# AE402FA0E5597LE0_CM55_HP_View register map
Vendor: Alif Semiconductor; Series: E4; File version: 1.0
CPU: CM55 r1p0, selectable endian, MPU, FPU, double-precision FPU, DSP, VTOR, 8 interrupt priority bits, 1 SAU regions
Registers are 32-bit, read-write, reset 0x0 unless marked. A register's access mark holds for its fields unless they carry their own. Offsets are from the block's base; [hi:lo] are bit positions; 'fields as' and 'values as' point back to an identical list.

## ETH (part 3 of 4)
Base 0x48100000
0xB18 ETH_MAC_TIMESTAMP_ADDEND — Timestamp Addend Register
  [31:0] TSAR — Timestamp Addend Register This field indicates the 32-bit time value to be added to the Accumulator register to achieve time synchronization.
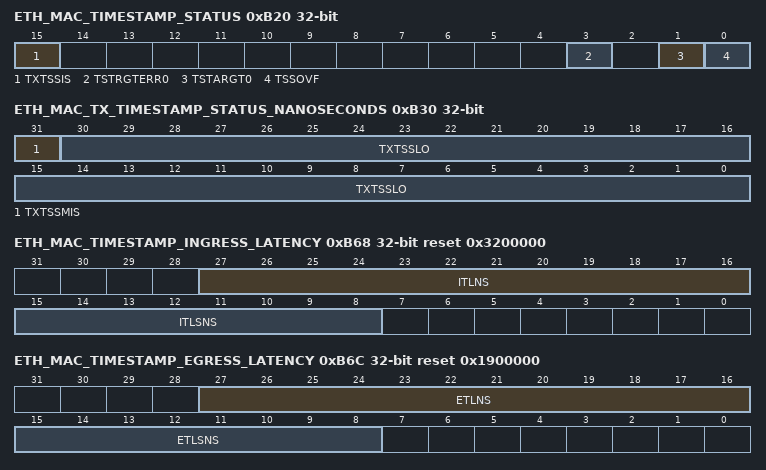
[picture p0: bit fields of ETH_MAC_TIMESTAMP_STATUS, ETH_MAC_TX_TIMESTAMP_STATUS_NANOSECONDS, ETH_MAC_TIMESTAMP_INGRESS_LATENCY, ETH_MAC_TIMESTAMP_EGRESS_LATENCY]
0xB20 ETH_MAC_TIMESTAMP_STATUS ro — Timestamp Status Register
  [15] TXTSSIS — Tx Timestamp Status Interrupt Status When drop transmit status is enabled in MTL, this bit is set when the captured transmit timestamp is updated in the ETH_MAC_TX_TIMESTAMP_STATUS_NANOSECONDS and ETH_MAC_TX_TIMESTAMP_STATUS_SECONDS registers. This bit is cleared when the ETH_MAC_TX_TIMESTAMP_STATUS_SECONDS register is read (or write to ETH_MAC_TX_TIMESTAMP_STATUS_SECONDS register when the ETH_MAC_CSR_SW_CTRL[RCWE] bit is set).
    0=Tx timestamp status interrupt status not detected; 1=Tx timestamp status interrupt status detected
  [3] TSTRGTERR0 — Timestamp Target Time Error This bit is set when the latest target time programmed in the ETH_MAC_PPS0_TARGET_TIME_SECONDS and ETH_MAC_PPS0_TARGET_TIME_NANOSECONDS registers elapses. Access restriction applies. Clears on read (or this bit is written to 1 when the ETH_MAC_CSR_SW_CTRL[RCWE] bit is set). Self-set to 1 on internal event.
    0=Timestamp target time error status not detected; 1=Timestamp target time error status detected
  [1] TSTARGT0 — Timestamp Target Time Reached When this bit is set, it indicates that the value of system time is greater than or equal to the value specified in the ETH_MAC_PPS0_TARGET_TIME_SECONDS and ETH_MAC_PPS0_TARGET_TIME_NANOSECONDS registers. Access restriction applies. Clears on read (or this bit is written to 1 when the ETH_MAC_CSR_SW_CTRL[RCWE] bit is set). Self-set to 1 on internal event.
    0=Timestamp target time reached status not detected; 1=Timestamp target time reached status detected
  [0] TSSOVF — Timestamp Seconds Overflow When this bit is set, it indicates that the ETH_MAC_SYSTEM_TIME_SECONDS[TSS] value has overflowed beyond 0xFFFF_FFFF. Access restriction applies. Clears on read (or this bit is written to 1 when the ETH_MAC_CSR_SW_CTRL[RCWE] bit is set). Self-set to 1 on internal event.
    0=Timestamp seconds overflow status not detected; 1=Timestamp seconds overflow status detected
0xB24 ETH_MAC_RX_DOMAIN_TIME_INCR — Rx Domain Time Increment Register
  [31:16] RXNS — Receive Domain Time Increment Value in Nanoseconds This field indicates the Nanosecond part of the increment value of the PTP time maintained in Receive clock domain that is used for timestamping.
0xB28 ETH_MAC_TX_DOMAIN_TIME_INCR — Tx Domain Time Increment Register
  [31:16] TXNS — Transmit Domain Time Increment Value in Nanoseconds This field indicates the Nanosecond part of the increment value of the PTP time maintained in Transmit clock domain that is used for timestamping.
0xB30 ETH_MAC_TX_TIMESTAMP_STATUS_NANOSECONDS ro — Transmit Timestamp Status Nanoseconds Register
  [31] TXTSSMIS — Transmit Timestamp Status Missed When this bit is set, it indicates one of the following: The timestamp of the current packet is ignored if the ETH_MAC_TIMESTAMP_CONTROL[TXTSSTSM] bit is reset The timestamp of the previous packet is overwritten with timestamp of the current packet if the ETH_MAC_TIMESTAMP_CONTROL[TXTSSTSM] bit is set. Access restriction applies. Clears on read. Self-set to 1 on internal event.
    0=Transmit timestamp status missed status not detected; 1=Transmit timestamp status missed status detected
  [30:0] TXTSSLO — Transmit Timestamp Status Low This field contains the 31 bits of the Nanoseconds field of the Transmit packet's captured timestamp.
0xB34 ETH_MAC_TX_TIMESTAMP_STATUS_SECONDS ro — Transmit Timestamp Status Seconds Register
  [31:0] TXTSSHI — Transmit Timestamp Status High This field contains the lower 32 bits of the Seconds field of Transmit packet's captured timestamp.
0xB58 ETH_MAC_TIMESTAMP_INGRESS_CORR_NANOSECOND — Timestamp Ingress Correction Nanoseconds Register
  [31:0] TSIC — Timestamp Ingress Correction This field contains the ingress path correction value as defined by the Ingress Correction expression.
0xB5C ETH_MAC_TIMESTAMP_EGRESS_CORR_NANOSECOND — Timestamp Egress Correction Nanoseconds Register
  [31:0] TSEC — Timestamp Egress Correction This field contains the nanoseconds part of the egress path correction value as defined by the Egress Correction expression.
0xB68 ETH_MAC_TIMESTAMP_INGRESS_LATENCY ro reset 0x3200000 — Ingress MAC latency Register
  [27:16] ITLNS — Ingress Timestamp Latency, in nanoseconds This register holds the average latency in nanoseconds between the input ports (ETH_RXD[1-0]) of MAC and the actual point (RMII) where the ingress timestamp is taken.
  [15:8] ITLSNS — Ingress Timestamp Latency, in sub-nanoseconds This register holds the average latency in sub-nanoseconds between the input ports (ETH_RXD[1-0]) of MAC and the actual point (RMII) where the ingress timestamp is taken.
0xB6C ETH_MAC_TIMESTAMP_EGRESS_LATENCY ro reset 0x1900000 — Egress MAC latency Register
  [27:16] ETLNS — Egress Timestamp Latency, in nanoseconds This register holds the average latency in nanoseconds between the actual point (RMII) where the egress timestamp is taken and the output ports (ETH_TXD[1-0]) of the MAC.
  [15:8] ETLSNS — Egress Timestamp Latency, in sub-nanoseconds This register holds the average latency in sub-nanoseconds between the actual point (RMII) where the egress timestamp is taken and the output ports (ETH_TXD[1-0]) of the MAC.
0xB70 ETH_MAC_PPS_CONTROL — PPS Control Register
  [3:0] PPSCTRL — Pulse Per Second (PPS) Frequency Control This field controls the PPS frequency. The default value of PPSCTRL is 0x0, and the PPS frequency is 1 pulse every second. For other values of PPSCTRL, the PPS becomes a generated clock of the following frequencies: Note: In the binary rollover mode, the PPS frequency has a duty cycle of 50 percent with these frequencies. In the digital rollover mode, the PPS frequency is an average number. The actual clock is of different frequency that gets synchronized every second. For example: When PPSCTRL = 0x1, the PPS (1 Hz) has a low period of 537 ms and a high period of 463 ms When PPSCTRL = 0x2, the PPS (2 Hz) is a sequence of: - One clock of 50 percent duty cycle and 537 ms period - Second clock of 463 ms period (268 ms low and 195 ms high) When PPSCTRL = 0x3, the PPS (4 Hz) is a sequence of: - Fourth clock of 195 ms period (134 ms low and 61 ms high) This behavior is because of the non-linear toggling of bits in the digital rollover mode in the ETH_MAC_SYSTEM_TIME_NANOSECONDS register.
    1=The binary rollover is 2 Hz, and the digital rollover is 1 Hz; 2=The binary rollover is 4 Hz, and the digital rollover is 2 Hz; 3=The binary rollover is 8 Hz, and the digital rollover is 4 Hz; 4=The binary rollover is 16 Hz, and the digital rollover is 8 Hz; 15=The binary rollover is 32.768 kHz and the digital rollover is 16.384 kHz
0xB80 ETH_MAC_PPS0_TARGET_TIME_SECONDS — PPS0 Target Time Seconds Register
  [31:0] TSTRH0 — PPS Target Time Seconds This field stores the time in seconds. When the timestamp value matches or exceeds both ETH_MAC_PPS0_TARGET_TIME_SECONDS and ETH_MAC_PPS0_TARGET_TIME_NANOSECONDS registers, the MAC generates an interrupt (if enabled).
0xB84 ETH_MAC_PPS0_TARGET_TIME_NANOSECONDS — PPS0 Target Time Nanoseconds Register
  [30:0] TTSL0 — Target Time Low for PPS Register This register stores the time in (signed) nanoseconds. When the value of the timestamp matches the value in both ETH_MAC_PPS0_TARGET_TIME_SECONDS and ETH_MAC_PPS0_TARGET_TIME_NANOSECONDS registers, the MAC generates an interrupt (if enabled). When the ETH_MAC_TIMESTAMP_CONTROL[TSCTRLSSR] bit is reset, this value must be (time in ns / 0.465). When the ETH_MAC_TIMESTAMP_CONTROL[TSCTRLSSR] bit is set, this value must not exceed 0x3B9A_C9FF. Access restriction applies. Setting 1 sets. Self-cleared. Setting 0 has no effect.
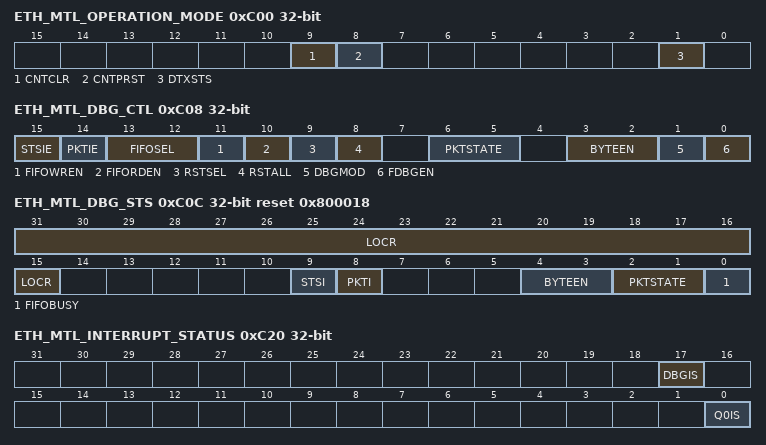
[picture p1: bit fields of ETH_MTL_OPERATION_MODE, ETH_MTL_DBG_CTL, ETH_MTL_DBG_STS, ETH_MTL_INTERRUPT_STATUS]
0xC00 ETH_MTL_OPERATION_MODE — Operation Mode Register
  [9] CNTCLR — Counters Reset When this bit is set, all counters are reset. This bit is cleared automatically after 1 clock cycle. If this bit is set along with the CNTPRST bit, CNTPRST has precedence. Access restrictions apply. MAC initiates the counters reset when application writes 1. MAC writes 0 after the counters reset is complete. MAC ignores when application writes 0.
    0=Counters are not reset; 1=All counters are reset
  [8] CNTPRST — Counters Preset When this bit is set, The ETH_MTL_TXQ0_UNDERFLOW register is initialized/preset to 0x7F0. The ETH_MTL_RXQ0_MISSED_PACKET_OVERFLOW_CNT[MISPKTCNT] and ETH_MTL_RXQ0_MISSED_PACKET_OVERFLOW_CNT[OVFPKTCNT] fields are initialized/preset to 0x7F0. MAC initiates the counters reset when application writes 1. MAC writes 0 after the counters reset is complete. MAC ignores when application writes 0.
    0=Counters preset is disabled; 1=Counters preset is enabled
  [1] DTXSTS — Drop Transmit Status When this bit is set, the Tx packet status received from the MAC is dropped in the MTL. When this bit is reset, the Tx packet status received from the MAC is forwarded to the application.
    0=Drop transmit status is disabled; 1=Drop transmit status is enabled
0xC08 ETH_MTL_DBG_CTL — FIFO Debug Access Control and Status Register
  [15] STSIE — Transmit Status Available Interrupt Status Enable When this bit is set, an interrupt is generated when Transmit status is available in slave mode.
    0=Transmit packet available interrupt status is disabled; 1=Transmit packet available interrupt status is enabled
  [14] PKTIE — Receive Packet Available Interrupt Status Enable When this bit is set, an interrupt is generated when EOP of received packet is written to the Rx FIFO.
    0=Receive packet available interrupt status is disabled; 1=Receive packet available interrupt status is enabled
  [13:12] FIFOSEL — FIFO Selected for Access This field indicates the FIFO selected for debug access:
    0=Tx FIFO; 1=Tx Status FIFO (only read access when SLVMOD is set) / DC Memory FIFO read-write access when DBGMOD is set; 2=TSO FIFO (cannot be accessed when SLVMOD is set); 3=Rx FIFO
  [11] FIFOWREN — FIFO Write Enable When this bit is set, it enables the Write operation on selected FIFO when FIFO Debug Access is enabled. This bit must not be written to 1 when FIFO Debug Access is not enabled, that is FDBGEN bit is 0. Access restriction applies. Self-cleared. Setting 0 clears. Setting 1 sets.
    0=FIFO write is disabled; 1=FIFO write is enabled
  [10] FIFORDEN — FIFO Read Enable When this bit is set, it enables the Read operation on selected FIFO when FIFO Debug Access is enabled. This bit must not be written to 1 when FIFO Debug Access is not enabled, that is FDBGEN bit is 0. Access restriction applies. Self-cleared. Setting 0 clears. Setting 1 sets.
    0=FIFO read is disabled; 1=FIFO read is enabled
  [9] RSTSEL — Reset Pointers of Selected FIFO When this bit is set, the pointers of the currently-selected FIFO are reset when FIFO Debug Access is enabled. This bit must not be written to 1 when FIFO Debug Access is not enabled, that is FDBGEN bit is 0. Access restriction applies. Self-cleared. Setting 0 clears. Setting 1 sets.
    0=Reset pointers of selected FIFO is disabled; 1=Reset pointers of selected FIFO is enabled
  [8] RSTALL — Reset All Pointers When this bit is set, the pointers of all FIFOs are reset when FIFO Debug Access is enabled. This bit must not be written to 1 when FIFO Debug Access is not enabled, that is FDBGEN bit is 0. Access restriction applies. Self-cleared. Setting 0 clears. Setting 1 sets.
    0=Reset all pointers is disabled; 1=Reset all pointers is enabled
  [6:5] PKTSTATE — Encoded Packet State This field is used to write the control information to the Tx FIFO or Rx FIFO. Tx FIFO: 0x0: Packet data 0x1: Control word 0x2: SOP data 0x3: EOP data Rx FIFO: 0x0: Packet data 0x1: Normal status 0x2: Last status 0x3: EOP
  [3:2] BYTEEN — Byte Enables This field indicates the number of data bytes valid in the data register during Write operation. This is valid only when PKTSTATE is 0x2 (EOP) and Tx FIFO or Rx FIFO is selected.
    0=Byte 0 valid; 1=Byte 0 and Byte 1 are valid; 2=Byte 0, Byte 1, and Byte 2 are valid; 3=All four bytes are valid
  [1] DBGMOD — Debug Mode Access to FIFO When this bit is set, it indicates that the current access to the FIFO is read, write, and debug access (that is, data can be written and read to specified or all locations through FIFO Debug Interface). In this mode, the following access types are allowed: - Read and Write access to Tx FIFO, TSO FIFO, DCACHE FIFO and Rx FIFO - Read access is allowed to Tx Status FIFO. When this bit is reset, it indicates that the current access to the FIFO is slave access bypassing the DMA (that is, packets can be transmitted or received through FIFO Debug Interface). In this mode, the following access are allowed: - Write access to the Tx FIFO - Read access to the Rx FIFO and Tx Status FIFO
    0=Debug mode access to FIFO is disabled; 1=Debug mode access to FIFO is enabled
  [0] FDBGEN — FIFO Debug Access Enable When this bit is set, it indicates that the debug mode access to the FIFO through CSR Slave Interface is enabled. When this bit is reset, it indicates that the FIFO can be accessed only through a master interface.
    0=FIFO debug access through CSR Slave Interface is disabled; 1=FIFO debug access through CSR Slave Interface is enabled
0xC0C ETH_MTL_DBG_STS reset 0x800018 — FIFO Debug Status Register
  [31:15] LOCR ro — Remaining Locations in the FIFO Slave Access Mode: This field indicates the space available in the selected FIFO. Debug Access Mode: This field contains the Write or Read pointer value of the selected FIFO during Write or Read operation, respectively.
  [9] STSI — Transmit Status Available Interrupt Status When set, this bit indicates that the Slave mode Tx packet is transmitted, and the status is available in Tx Status FIFO. This bit is reset when 1 is written to this bit.
    0=Transmit status available interrupt status not detected; 1=Transmit status available interrupt status detected
  [8] PKTI — Receive Packet Available Interrupt Status When set, this bit indicates that MAC layer has written the EOP of received packet to the Rx FIFO. This bit is reset when 1 is written to this bit.
    0=Receive packet available interrupt status not detected; 1=Receive packet available interrupt status detected
  [4:3] BYTEEN ro — Byte Enables This field indicates the number of data bytes valid in the data register during Read operation. This is valid only when PKTSTATE is 0x2 (EOP) and Tx FIFO or Rx FIFO is selected.
    values as ETH_MTL_DBG_CTL.BYTEEN
  [2:1] PKTSTATE ro — Encoded Packet State This field is used to get the control or status information of the selected FIFO. Tx FIFO: 0x0: Packet data 0x1: Control word 0x2: SOP data 0x3: EOP data Rx FIFO: 0x0: Packet data 0x1: Normal status 0x2: Last status 0x3: EOP
  [0] FIFOBUSY ro — FIFO Busy When set, this bit indicates that a FIFO operation is in progress in the MAC and content of the following fields is not valid: All other fields of this register All fields of the ETH_MTL_FIFO_DEBUG_DATA register
    0=FIFO busy not detected; 1=FIFO busy detected
0xC10 ETH_MTL_FIFO_DEBUG_DATA — FIFO Debug Data Register
  [31:0] FDBGDATA — FIFO Debug Data During debug or slave access write operation, this field contains the data to be written to the Tx FIFO, Rx FIFO, or TSO FIFO. During debug or slave access read operation, this field contains the data read from the Tx FIFO, Rx FIFO, TSO FIFO, or Tx Status FIFO.
0xC20 ETH_MTL_INTERRUPT_STATUS ro — MTL Interrupt Status Register
  [17] DBGIS — Debug Interrupt status This bit indicates an interrupt event during the slave access. To reset this bit, the application must read the ETH_MTL_DBG_STS register to get the exact cause of the interrupt and clear its source.
    0=Debug interrupt status not detected; 1=Debug interrupt status detected
  [0] Q0IS — Queue 0 Interrupt status This bit indicates that there is an interrupt from Queue 0. To reset this bit, the application must read Queue 0 Interrupt Control and Status register to get the exact cause of the interrupt and clear its source.
    0=Queue 0 interrupt status not detected; 1=Queue 0 interrupt status detected
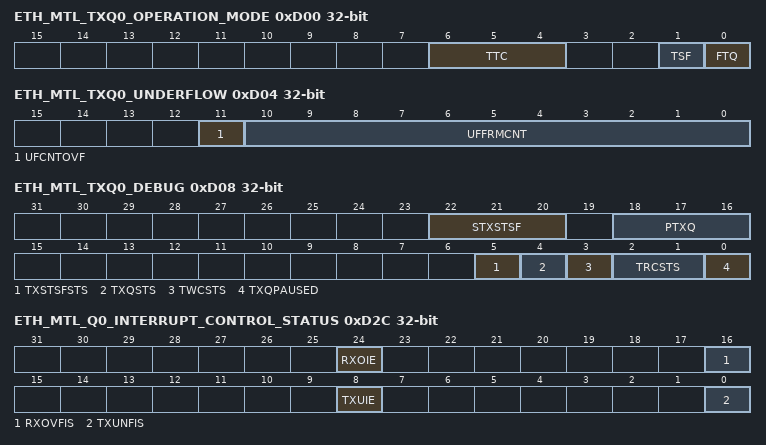
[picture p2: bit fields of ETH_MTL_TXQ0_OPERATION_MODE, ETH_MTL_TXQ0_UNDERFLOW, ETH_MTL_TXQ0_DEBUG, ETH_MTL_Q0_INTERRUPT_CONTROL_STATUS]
0xD00 ETH_MTL_TXQ0_OPERATION_MODE — Queue 0 Transmit Operation Mode Register
  [6:4] TTC — Transmit Threshold Control These bits control the threshold level of the MTL Tx Queue. The transmission starts when the packet size within the MTL Tx Queue is larger than the threshold. In addition, full packets with length less than the threshold are also transmitted. These bits are used only when the TSF bit is reset.
    0=32; 1=64; 2=96; 3=128; 4=192; 5=256; 6=384; 7=512
  [1] TSF — Transmit Store and Forward When this bit is set, the transmission starts when a full packet resides in the MTL Tx Queue. When this bit is set, the TTC value is ignored. This bit should be changed only when the transmission is stopped.
    0=Transmit store and forward is disabled; 1=Transmit store and forward is enabled
  [0] FTQ — Flush Transmit Queue When this bit is set, the Tx Queue controller logic is reset to its default values. Therefore, all the data in the Tx Queue is lost or flushed. This bit is internally reset when the flushing operation is complete. Until this bit is reset, the user must not write to the ETH_MTL_TXQ0_OPERATION_MODE register. The data which is already accepted by the MAC transmitter is not flushed. It is scheduled for transmission and results in underflow and runt packet transmission. Note: The flush operation is complete only when the Tx Queue is empty and the application has accepted the pending Tx Status of all transmitted packets. Access restrictions apply. MAC initiates the Tx queue flush when application writes 1. MAC writes 0 after the Tx queue flush is complete. MAC ignores when application writes 0.
    0=Flush transmit queue is disabled; 1=Flush transmit queue is enabled
0xD04 ETH_MTL_TXQ0_UNDERFLOW ro — Queue 0 Underflow Counter Register
  [11] UFCNTOVF — Overflow Bit for Underflow Packet Counter This bit is set every time the Tx Queue Underflow Packet Counter field overflows, that is, it has crossed the maximum count. In such a scenario, the overflow packet counter is reset to all-zeros and this bit indicates that the rollover happened. Access restriction applies. Clears on read. Self-set to 1 on internal event.
    0=Overflow not detected for underflow packet counter; 1=Overflow detected for underflow packet counter
  [10:0] UFFRMCNT — Underflow Packet Counter This field indicates the number of packets aborted by the controller because of Tx Queue Underflow. This counter is incremented each time the MAC aborts outgoing packet because of underflow. Access restriction applies. Clears on read. Self-set to 1 on internal event.
0xD08 ETH_MTL_TXQ0_DEBUG ro — Queue 0 Transmit Debug Register
  [22:20] STXSTSF — Number of Status Words in Tx Status FIFO of Queue This field indicates the current number of status in the Tx Status FIFO of this queue. When the ETH_MTL_OPERATION_MODE[DTXSTS] bit is set to 1, this field does not reflect the number of status words in Tx Status FIFO.
  [18:16] PTXQ — Number of Packets in the Transmit Queue This field indicates the current number of packets in the Tx Queue. When the ETH_MTL_OPERATION_MODE[DTXSTS] bit is set to 1, this field does not reflect the number of packets in the Transmit queue.
  [5] TXSTSFSTS — MTL Tx Status FIFO Full Status When high, this bit indicates that the MTL Tx Status FIFO is full. Therefore, the MTL cannot accept any more packets for transmission.
    0=MTL Tx Status FIFO full status is not detected; 1=MTL Tx Status FIFO full status is detected
  [4] TXQSTS — MTL Tx Queue Not Empty Status When this bit is high, it indicates that the MTL Tx Queue is not empty and some data is left for transmission.
    0=MTL Tx Queue not empty status is not detected; 1=MTL Tx Queue not empty status is detected
  [3] TWCSTS — MTL Tx Queue Write Controller Status When high, this bit indicates that the MTL Tx Queue Write Controller is active, and it is transferring the data to the Tx Queue.
    0=MTL Tx Queue write controller status is not detected; 1=MTL Tx Queue write controller status is detected
  [2:1] TRCSTS — MTL Tx Queue Read Controller Status This field indicates the state of the Tx Queue Read Controller:
    0=Idle state; 1=Read state (transferring data to the MAC transmitter); 2=Waiting for pending Tx status from the MAC transmitter; 3=Flushing the Tx Queue because of the packet abort request from the MAC
  [0] TXQPAUSED — Transmit Queue in Pause When this bit is high and the Rx flow control is enabled, it indicates that the Tx Queue is in the Pause condition (in the full-duplex only mode) because of the following: Reception of the PFC packet for the priorities assigned to the Tx Queue when PFC is enabled Reception of 802.3x Pause packet when PFC is disabled
    0=Transmit queue in pause status is not detected; 1=Transmit queue in pause status is detected
0xD2C ETH_MTL_Q0_INTERRUPT_CONTROL_STATUS — Queue 0 Interrupt Enable and Status Register
  [24] RXOIE — Receive Queue Overflow Interrupt Enable When this bit is set, the receive queue overflow interrupt is enabled. When this bit is reset, the Receive Queue Overflow interrupt is disabled.
    0=Receive queue overflow interrupt is disabled; 1=Receive queue overflow interrupt is enabled
  [16] RXOVFIS — Receive Queue Overflow Interrupt Status This bit indicates that the receive queue had an overflow while receiving the packet. If a partial packet is transferred to the application, the overflow status is set in RDES3[21]. This bit is cleared when the application writes 1 to this bit. Access restriction applies. Self-set to 1 on internal event. Setting 1 clears. Setting 0 has no effect.
    0=Receive queue overflow interrupt status not detected; 1=Receive queue overflow interrupt status detected
  [8] TXUIE — Transmit Queue Underflow Interrupt Enable When this bit is set, the transmit queue underflow interrupt is enabled. When this bit is reset, the Transmit Queue Underflow interrupt is disabled.
    0=Transmit queue underflow interrupt status is disabled; 1=Transmit queue underflow interrupt status is enabled
  [0] TXUNFIS — Transmit Queue Underflow Interrupt Status This bit indicates that the transmit queue had an underflow while transmitting the packet. Transmission is suspended and an Underflow Error TDES3[2] is set. This bit is cleared when the application writes 1 to this bit. Access restriction applies. Self-set to 1 on internal event. Setting 1 clears. Setting 0 has no effect.
    0=Transmit queue underflow interrupt status not detected; 1=Transmit queue underflow interrupt status detected
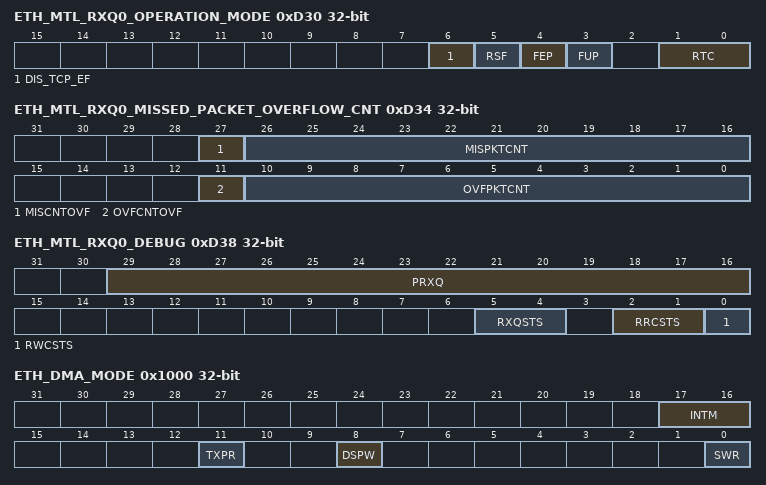
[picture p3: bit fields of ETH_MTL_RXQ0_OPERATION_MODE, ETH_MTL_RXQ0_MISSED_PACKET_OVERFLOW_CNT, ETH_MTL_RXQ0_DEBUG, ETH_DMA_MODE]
0xD30 ETH_MTL_RXQ0_OPERATION_MODE — Queue 0 Receive Operation Mode Register
  [6] DIS_TCP_EF — Disable Dropping of TCP/IP Checksum Error Packets When this bit is set, the MAC does not drop the packets which only have the errors detected by the Receive Checksum Offload engine. Such packets have errors only in the encapsulated payload. There are no errors (including FCS error) in the Ethernet packet received by the MAC. When this bit is reset, all error packets are dropped if the FEP bit is reset.
    0=Dropping of TCP/IP checksum error packets is enabled; 1=Dropping of TCP/IP checksum error packets is disabled
  [5] RSF — Receive Queue Store and Forward When this bit is set, the ETH module reads a packet from the Rx Queue only after the complete packet has been written to it, ignoring the RTC field of this register. When this bit is reset, the Rx Queue operates in the Threshold (cut-through) mode, subject to the threshold specified by the RTC field of this register.
    0=Receive queue store and forward is disabled; 1=Receive queue store and forward is enabled
  [4] FEP — Forward Error Packets When this bit is reset, the Rx Queue drops packets with error status (CRC error, GMII_ER, watchdog timeout, or overflow). However, if the start byte (write) pointer of a packet is already transferred to the read controller side (in Threshold mode), the packet is not dropped. When this bit is set, all packets except the runt error packets are forwarded to the application or DMA. If the RSF bit is set and the Rx Queue overflows when a partial packet is written, the packet is dropped irrespective of the setting of this bit. However, if the RSF bit is reset and the Rx Queue overflows when a partial packet is written, a partial packet might be forwarded to the application or DMA.
    0=Forward error packets is disabled; 1=Forward error packets is enabled
  [3] FUP — Forward Undersized Good Packets When this bit is set, the Rx Queue forwards the undersized good packets (packets with no error and length less than 64 bytes), including pad-bytes and CRC. When this bit is reset, the Rx Queue drops all packets of less than 64 bytes, unless a packet is already transferred because of the lower value of Rx Threshold, for example, RTC = 01.
    0=Forward undersized good packets is disabled; 1=Forward undersized good packets is enabled
  [1:0] RTC — Receive Queue Threshold Control These bits control the threshold level of the MTL Rx Queue (in bytes):The received packet is transferred to the application or DMA when the packet size within the MTL Rx Queue is larger than the threshold. In addition, full packets with length less than the threshold are automatically transferred. This field is valid only when the RSF bit is zero. This field is ignored when the RSF bit is set to 1.
    0=64; 1=32; 2=96; 3=128
0xD34 ETH_MTL_RXQ0_MISSED_PACKET_OVERFLOW_CNT ro — Queue 0 Missed Packet and Overflow Counter Register
  [27] MISCNTOVF — Missed Packet Counter Overflow Bit When set, this bit indicates that the Rx Queue Missed Packet Counter crossed the maximum limit. Access restriction applies. Clears on read. Self-set to 1 on internal event.
    0=Missed packet counter overflow not detected; 1=Missed packet counter overflow detected
  [26:16] MISPKTCNT — Missed Packet Counter This counter is incremented by 1 when the DMA discards the packet because of buffer unavailability. Access restriction applies. Clears on read. Self-set to 1 on internal event.
  [11] OVFCNTOVF — Overflow Counter Overflow Bit When set, this bit indicates that the Rx Queue Overflow Packet Counter field crossed the maximum limit. Access restriction applies. Clears on read. Self-set to 1 on internal event.
    0=Overflow counter overflow not detected; 1=Overflow counter overflow detected
  [10:0] OVFPKTCNT — Overflow Packet Counter This field indicates the number of packets discarded by the ETH module because of Receive queue overflow. This counter is incremented each time the ETH module discards an incoming packet because of overflow. Access restriction applies. Clears on read. Self-set to 1 on internal event.
0xD38 ETH_MTL_RXQ0_DEBUG ro — Queue 0 Receive Debug Register
  [29:16] PRXQ — Number of Packets in Receive Queue This field indicates the current number of packets in the Rx Queue. The theoretical maximum value for this field is 256KB/16B = 16KB Packets, that is, Max_Queue_Size/Min_Packet_Size.
  [5:4] RXQSTS — MTL Rx Queue Fill-Level Status This field gives the status of the fill-level of the Rx Queue:
    0=Rx Queue empty; 1=Rx Queue fill-level below flow-control deactivate threshold; 2=Rx Queue fill-level above flow-control activate threshold; 3=Rx Queue full
  [2:1] RRCSTS — MTL Rx Queue Read Controller State This field gives the state of the Rx Queue Read controller:
    0=Idle state; 1=Reading packet data; 2=Reading packet status (or timestamp); 3=Flushing the packet data and status
  [0] RWCSTS — MTL Rx Queue Write Controller Active Status When high, this bit indicates that the MTL Rx Queue Write controller is active, and it is transferring a received packet to the Rx Queue.
    0=MTL Rx Queue write controller active status not detected; 1=MTL Rx Queue write controller active status detected
0x1000 ETH_DMA_MODE — Bus Mode Register
  [17:16] INTM — Interrupt Mode This field defines the interrupt mode of the ETH module and changes the behavior of the ETH_SBD_IRQ signal. It also changes the behavior of the ETH_DMA_CH0_STATUS[RI] and ETH_DMA_CH0_STATUS[TI] bits.
    0=ETH_SBD_IRQ is asserted when corresponding interrupts are enabled, and cleared only when software clears the corresponding RI/TI status bits; 1=ETH_SBD_IRQ is not asserted on TX/RX packet transfer completion event; 2=ETH_SBD_IRQ is not asserted on TX/RX packet transfer completion event
  [11] TXPR — Transmit Priority When set, this bit indicates that the Tx DMA has priority over the Rx DMA during arbitration for the system-side bus.
    0=Transmit Priority is disabled; 1=Transmit Priority is enabled
  [8] DSPW — Descriptor Posted Write When this bit is set to 0, the descriptor writes are non-posted. When this bit is set to 1, the descriptor writes are non-posted only when IOC = 1 (Interrupt on completion) in last descriptor; otherwise, the descriptor writes are always posted.
    0=Descriptor posted write is disabled; 1=Descriptor posted write is enabled
  [0] SWR — Software Reset When this bit is set, the MAC and the DMA controller reset the logic and all internal registers of the DMA, MTL, and MAC. This bit is automatically cleared after the reset operation is complete in all ETH module clock domains. Before reprogramming any ETH module register, a value of zero should be read in this bit. This bit must be read at least 4 CLK_CSR cycles after it is written to 1. Note: The reset operation is complete only when the ETH module has de-asserted all resets in all active clock domains. Therefore, it is essential that all PHY input clocks of the selected PHY interface are present for the completion of the software reset. The time required to complete the software reset operation depends on the frequency of the slowest active clock. Access restrictions apply. MAC initiates the software reset when application writes 1. MAC writes 0 after the software reset is complete. MAC ignores when application writes 0.
    0=Software reset is disabled; 1=Software reset is enabled
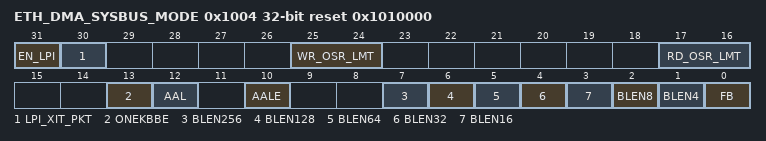
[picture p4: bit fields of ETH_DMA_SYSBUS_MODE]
0x1004 ETH_DMA_SYSBUS_MODE reset 0x1010000 — System Bus Mode Register
  [31] EN_LPI — Enable Low Power Interface (LPI) When set to 1, this bit enables the LPI mode and accepts the LPI request from the AXI System Clock controller. When set to 0, this bit disables the LPI mode and denies the LPI request from the AXI System Clock controller.
    0=LPI is disabled; 1=LPI is enabled
  [30] LPI_XIT_PKT — Unlock on Magic Packet or Remote Wake-Up Packet When set to 1, this bit enables the AXI master to come out of the LPI mode only when the magic packet or remote wake-up packet is received. When set to 0, this bit enables the AXI master to come out of the LPI mode when any packet is received.
    0=Unlock on magic packet or remote wake-up packet is disabled; 1=Unlock on magic packet or remote wake-up packet is enabled
  [25:24] WR_OSR_LMT — AXI Maximum Write Outstanding Request Limit This value limits the maximum outstanding request on the AXI write interface. Maximum outstanding requests = WR_OSR_LMT + 1.
  [17:16] RD_OSR_LMT — AXI Maximum Read Outstanding Request Limit This value limits the maximum outstanding request on the AXI read interface. Maximum outstanding requests = RD_OSR_LMT + 1.
  [13] ONEKBBE — 1KB Boundary Crossing Enable for the AXI Master When set, the burst transfers performed by the AXI master do not cross 1KB boundary. When reset, the burst transfers performed by the AXI master do not cross 4KB boundary.
    0=1KB boundary crossing for the AXI master beats is disabled; 1=1KB boundary crossing for the AXI master beats is enabled
  [12] AAL — Address-Aligned Beats When this bit is set to 1, the AXI master performs address-aligned burst transfers on Read and Write channels.
    0=Address-aligned beats is disabled; 1=Address-aligned beats is enabled
  [10] AALE — Automatic AXI LPI enable When set to 1, enables the AXI master to enter into LPI state when there is no activity in the ETH module for number of system clock cycles programmed in the ETH_AXI_LPI_ENTRY_INTERVAL[LPIEI] field.
    0=Automatic AXI LPI is disabled; 1=Automatic AXI LPI is enabled
  [7] BLEN256 — AXI Burst Length 256 When set to - 1: the AXI master can select a burst length of 256 on the AXI interface. - 0: the AXI master cannot select a burst length of greater than 128 on the AXI interface.
    0=No effect; 1=AXI Burst Length 256
  [6] BLEN128 — AXI Burst Length 128 When set to - 1: the AXI master can select a burst length of 128 on the AXI interface. - 0: the AXI master cannot select a burst length of greater than 64 on the AXI interface.
    0=No effect; 1=AXI Burst Length 128
  [5] BLEN64 — AXI Burst Length 64 When set to - 1: the AXI master can select a burst length of 64 on the AXI interface. - 0: the AXI master cannot select a burst length of greater than 32 on the AXI interface.
    0=No effect; 1=AXI Burst Length 64
  [4] BLEN32 — AXI Burst Length 32 When set to - 1: the AXI master can select a burst length of 32 on the AXI interface. - 0: the AXI master cannot select a burst length of greater than 16 on the AXI interface.
    0=No effect; 1=AXI Burst Length 32
  [3] BLEN16 — AXI Burst Length 16 When this bit is set to 1 or the FB bit is set to 0, the AXI master can select a burst length of 16 on the AXI interface. When the FB bit is set to 0, setting this bit has no effect.
    0=No effect; 1=AXI burst length 16
  [2] BLEN8 — AXI Burst Length 8 When this bit is set to 1 or the FB bit is set to 0, the AXI master can select a burst length of 8 on the AXI interface. When the FB bit is set to 0, setting this bit has no effect.
    0=No effect; 1=AXI burst length 8
  [1] BLEN4 — AXI Burst Length 4 When this bit is set to 1 or the FB bit is set to 0, the AXI master can select a burst length of 4 on the AXI interface. When the FB bit is set to 0, setting this bit has no effect.
    0=No effect; 1=AXI burst length 4
  [0] FB — Fixed Burst Length When this bit is set to 1, the AXI master initiates burst transfers of specified lengths as given below. Burst transfers of length 1 When this bit is set to 0, the AXI master initiates burst transfers that are equal to or less than the maximum allowed burst length programmed in Bits[3-1].
    0=Fixed burst length is disabled; 1=Fixed burst length is enabled
